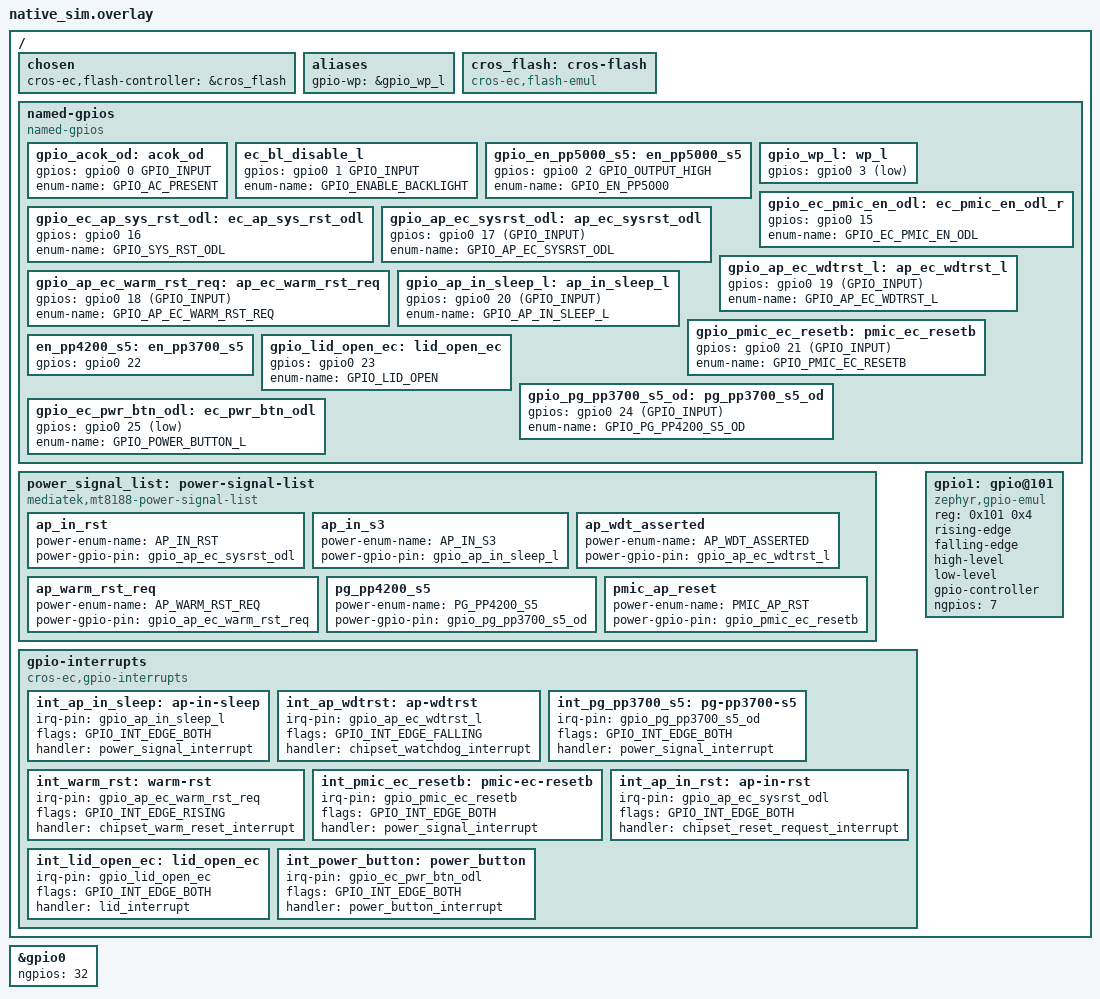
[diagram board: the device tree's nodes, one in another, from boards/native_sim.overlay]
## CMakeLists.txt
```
# Copyright 2025 The ChromiumOS Authors
# Use of this source code is governed by a BSD-style license that can be
# found in the LICENSE file.

cmake_minimum_required(VERSION 3.13.1)
find_package(Zephyr REQUIRED HINTS "${ZEPHYR_BASE}")
project(mtk_power)

# Include the local test directory for shimmed_test_tasks.h
zephyr_include_directories("${CMAKE_CURRENT_SOURCE_DIR}")

FILE(GLOB_RECURSE test_sources src/*.c)
target_sources(app PRIVATE ${test_sources})
```

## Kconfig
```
# Copyright 2025 The ChromiumOS Authors
# Use of this source code is governed by a BSD-style license that can be
# found in the LICENSE file.

source "Kconfig.zephyr"
```

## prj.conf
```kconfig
# Copyright 2025 The ChromiumOS Authors
# Use of this source code is governed by a BSD-style license that can be
# found in the LICENSE file.

CONFIG_ASSERT=y
CONFIG_TEST=y
CONFIG_ZTEST=y
CONFIG_ZTEST_ASSERT_VERBOSE=1
CONFIG_ZTEST_MOCKING=y

CONFIG_INPUT=y

# Print logs from Zephyr LOG_MODULE to stdout
CONFIG_UART_NATIVE_PTY_0_ON_STDINOUT=y

CONFIG_CROS_EC=y
CONFIG_EMUL=y
CONFIG_FLASH=y
CONFIG_GPIO=y
CONFIG_GPIO_GET_CONFIG=y
CONFIG_PLATFORM_EC=y
CONFIG_RING_BUFFER=y
CONFIG_SERIAL=y
CONFIG_SHELL_BACKEND_DUMMY=y
CONFIG_SHELL_BACKEND_DUMMY_BUF_SIZE=2000
CONFIG_SHELL_BACKEND_SERIAL=n
CONFIG_SHIMMED_TASKS=y

# MTK power sequencing
CONFIG_AP_ARM_MTK_MT8196=y
CONFIG_PLATFORM_EC_CHIPSET_RESUME_INIT_HOOK=y
CONFIG_PLATFORM_EC_EXTPOWER=y
CONFIG_PLATFORM_EC_EXTPOWER_GPIO=y
CONFIG_PLATFORM_EC_HOSTCMD=y
CONFIG_PLATFORM_EC_LID_SWITCH=y
CONFIG_PLATFORM_EC_POWERSEQ=y
CONFIG_PLATFORM_EC_POWERSEQ_HOST_SLEEP=y
CONFIG_PLATFORM_EC_POWERSEQ_MT8196=y
CONFIG_PLATFORM_EC_POWER_BUTTON=y
CONFIG_PLATFORM_EC_POWER_SLEEP_FAILURE_DETECTION=y
```

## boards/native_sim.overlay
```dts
/* Copyright 2025 The ChromiumOS Authors
 * Use of this source code is governed by a BSD-style license that can be
 * found in the LICENSE file.
 */

#include <board-overlays/native_sim.dts>
#include <dt-bindings/gpio_defines.h>
#include <cros/binman.dtsi>

/ {
	chosen {
		cros-ec,flash-controller = &cros_flash;
	};
	aliases {
		gpio-wp = &gpio_wp_l;
	};
	cros_flash: cros-flash {
		compatible = "cros-ec,flash-emul";
	};

	/*
	 * Keep these GPIOs in pin order.
	 * If you need to add one, make sure you increase
	 * ngpios in the gpio0 node further down.
	 */
	named-gpios {
		compatible = "named-gpios";

		gpio_acok_od: acok_od {
			gpios = <&gpio0 0 GPIO_INPUT>;
			enum-name = "GPIO_AC_PRESENT";
		};
		ec_bl_disable_l {
			gpios = <&gpio0 1 GPIO_INPUT>;
			enum-name = "GPIO_ENABLE_BACKLIGHT";
		};
		gpio_en_pp5000_s5: en_pp5000_s5 {
			gpios = <&gpio0 2 GPIO_OUTPUT_HIGH>;
			enum-name = "GPIO_EN_PP5000";
		};
		gpio_wp_l: wp_l {
			gpios = <&gpio0 3 (GPIO_INPUT | GPIO_ACTIVE_LOW)>;
		};
		gpio_ec_pmic_en_odl: ec_pmic_en_odl_r {
			gpios = <&gpio0 15 (GPIO_OUTPUT | GPIO_ACTIVE_HIGH | GPIO_OUTPUT_INIT_HIGH)>;
			enum-name = "GPIO_EC_PMIC_EN_ODL";
		};
		gpio_ec_ap_sys_rst_odl: ec_ap_sys_rst_odl {
			gpios = <&gpio0 16 (GPIO_OUTPUT | GPIO_ACTIVE_HIGH | GPIO_OUTPUT_INIT_HIGH)>;
			enum-name = "GPIO_SYS_RST_ODL";
		};
		gpio_ap_ec_sysrst_odl: ap_ec_sysrst_odl {
			gpios = <&gpio0 17 (GPIO_INPUT)>;
			enum-name = "GPIO_AP_EC_SYSRST_ODL";
		};
		gpio_ap_ec_warm_rst_req: ap_ec_warm_rst_req {
			gpios = <&gpio0 18 (GPIO_INPUT)>;
			enum-name = "GPIO_AP_EC_WARM_RST_REQ";
		};
		gpio_ap_ec_wdtrst_l: ap_ec_wdtrst_l {
			gpios = <&gpio0 19 (GPIO_INPUT)>;
			enum-name = "GPIO_AP_EC_WDTRST_L";
		};
		gpio_ap_in_sleep_l: ap_in_sleep_l {
			gpios = <&gpio0 20 (GPIO_INPUT)>;
			enum-name = "GPIO_AP_IN_SLEEP_L";
		};
		gpio_pmic_ec_resetb: pmic_ec_resetb {
			gpios = <&gpio0 21 (GPIO_INPUT)>;
			enum-name = "GPIO_PMIC_EC_RESETB";
		};
		/* a label to prevent build break in power sequencing */
		en_pp4200_s5: en_pp3700_s5 {
			gpios = <&gpio0 22 (GPIO_OUTPUT | GPIO_ACTIVE_HIGH | GPIO_OUTPUT_INIT_LOW)>;
		};
		gpio_lid_open_ec: lid_open_ec {
			/* GPIO_PULL_UP will cause this start asserted. */
			gpios = <&gpio0 23 (GPIO_INPUT | GPIO_PULL_UP)>;
			enum-name = "GPIO_LID_OPEN";
		};
		gpio_pg_pp3700_s5_od: pg_pp3700_s5_od {
			gpios = <&gpio0 24 (GPIO_INPUT)>;
			enum-name = "GPIO_PG_PP4200_S5_OD";
		};
		gpio_ec_pwr_btn_odl: ec_pwr_btn_odl {
			/* GPIO_PULL_UP will cause this start asserted,
			 * i.e. not pressed.
			 */
			gpios = <&gpio0 25 (GPIO_INPUT | GPIO_ACTIVE_LOW | GPIO_PULL_UP)>;
			enum-name = "GPIO_POWER_BUTTON_L";
		};
	};

	power_signal_list: power-signal-list {
		compatible = "mediatek,mt8188-power-signal-list";

		ap_in_rst {
			power-enum-name = "AP_IN_RST";
			power-gpio-pin = <&gpio_ap_ec_sysrst_odl>;
		};
		ap_in_s3 {
			power-enum-name = "AP_IN_S3";
			power-gpio-pin = <&gpio_ap_in_sleep_l>;
		};
		ap_wdt_asserted {
			power-enum-name = "AP_WDT_ASSERTED";
			power-gpio-pin = <&gpio_ap_ec_wdtrst_l>;
		};
		ap_warm_rst_req {
			power-enum-name = "AP_WARM_RST_REQ";
			power-gpio-pin = <&gpio_ap_ec_warm_rst_req>;
		};
		pg_pp4200_s5 {
			/*
			 * It's actually PP3700, but we don't change it and
			 * follow the legacy naming.
			 */
			power-enum-name = "PG_PP4200_S5";
			power-gpio-pin = <&gpio_pg_pp3700_s5_od>;
		};
		pmic_ap_reset {
			power-enum-name = "PMIC_AP_RST";
			power-gpio-pin = <&gpio_pmic_ec_resetb>;
		};
	};

	gpio-interrupts {
		compatible = "cros-ec,gpio-interrupts";

		int_ap_in_sleep: ap-in-sleep {
			irq-pin = <&gpio_ap_in_sleep_l>;
			flags = <GPIO_INT_EDGE_BOTH>;
			handler = "power_signal_interrupt";
		};
		int_ap_wdtrst: ap-wdtrst {
			irq-pin = <&gpio_ap_ec_wdtrst_l>;
			flags = <GPIO_INT_EDGE_FALLING>;
			handler = "chipset_watchdog_interrupt";
		};
		int_pg_pp3700_s5: pg-pp3700-s5 {
			irq-pin = <&gpio_pg_pp3700_s5_od>;
			flags = <GPIO_INT_EDGE_BOTH>;
			handler = "power_signal_interrupt";
		};
		int_warm_rst: warm-rst {
			irq-pin = <&gpio_ap_ec_warm_rst_req>;
			flags = <GPIO_INT_EDGE_RISING>;
			handler = "chipset_warm_reset_interrupt";
		};
		int_pmic_ec_resetb: pmic-ec-resetb {
			irq-pin = <&gpio_pmic_ec_resetb>;
			flags = <GPIO_INT_EDGE_BOTH>;
			handler = "power_signal_interrupt";
		};
		int_ap_in_rst: ap-in-rst {
			irq-pin = <&gpio_ap_ec_sysrst_odl>;
			flags = <GPIO_INT_EDGE_BOTH>;
			handler = "chipset_reset_request_interrupt";
		};
		int_lid_open_ec: lid_open_ec {
			irq-pin = <&gpio_lid_open_ec>;
			flags = <GPIO_INT_EDGE_BOTH>;
			handler = "lid_interrupt";
		};
		int_power_button: power_button {
			irq-pin = <&gpio_ec_pwr_btn_odl>;
			flags = <GPIO_INT_EDGE_BOTH>;
			handler = "power_button_interrupt";
		};
	};

	gpio1: gpio@101 {
		status = "okay";
		compatible = "zephyr,gpio-emul";
		reg = <0x101 0x4>;
		rising-edge;
		falling-edge;
		high-level;
		low-level;
		gpio-controller;
		#gpio-cells = <2>;
		ngpios = <7>;
	};
};

&gpio0 {
	ngpios = <32>;
};
```

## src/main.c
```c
/* Copyright 2025 The ChromiumOS Authors
 * Use of this source code is governed by a BSD-style license that can be
 * found in the LICENSE file.
 */

#include "console.h"
#include "ec_app_main.h"
#include "gpio.h"
#include "gpio_signal.h"
#include "hooks.h"
#include "host_command.h"
#include "include/power_button.h"
#include "lid_switch.h"
#include "power.h"
#include "power/mt8186.h"
#include "task.h"

#include <setjmp.h>

#include <zephyr/device.h>
#include <zephyr/devicetree.h>
#include <zephyr/drivers/gpio.h>
#include <zephyr/drivers/gpio/gpio_emul.h>
#include <zephyr/fff.h>
#include <zephyr/input/input.h>
#include <zephyr/kernel.h>
#include <zephyr/logging/log.h>
#include <zephyr/shell/shell_dummy.h>
#include <zephyr/ztest.h>

#include <dt-bindings/buttons.h>

LOG_MODULE_REGISTER(mtk_power, LOG_LEVEL_INF);

/* For simplicity, enforce that all the gpios are on the same controller. */
#define GPIO_DEVICE    \
	DEVICE_DT_GET( \
		DT_GPIO_CTLR(NAMED_GPIOS_GPIO_NODE(ap_ec_sysrst_odl), gpios))
#define ASSERT_SAME_CONTROLLER(x)                                           \
	BUILD_ASSERT(                                                       \
		DT_DEP_ORD(DT_GPIO_CTLR(                                    \
			NAMED_GPIOS_GPIO_NODE(ap_ec_sysrst_odl), gpios)) == \
		DT_DEP_ORD(DT_GPIO_CTLR(NAMED_GPIOS_GPIO_NODE(x), gpios)))

#define AP_IN_RST DT_GPIO_PIN(NAMED_GPIOS_GPIO_NODE(ap_ec_sysrst_odl), gpios)
ASSERT_SAME_CONTROLLER(ap_ec_sysrst_odl);
#define EC_AP_RST_L DT_GPIO_PIN(NAMED_GPIOS_GPIO_NODE(ec_ap_sys_rst_odl), gpios)
ASSERT_SAME_CONTROLLER(ec_ap_sys_rst_odl);
#define AP_IN_SLEEP DT_GPIO_PIN(NAMED_GPIOS_GPIO_NODE(ap_in_sleep_l), gpios)
ASSERT_SAME_CONTROLLER(ap_in_sleep_l);
#define AP_WARM_RST_REQ \
	DT_GPIO_PIN(NAMED_GPIOS_GPIO_NODE(ap_ec_warm_rst_req), gpios)
ASSERT_SAME_CONTROLLER(ap_ec_warm_rst_req);
#define AP_WDGT_RST_REQ \
	DT_GPIO_PIN(NAMED_GPIOS_GPIO_NODE(ap_ec_wdtrst_l), gpios)
ASSERT_SAME_CONTROLLER(ap_ec_wdtrst_l);
#define PG_PP3700_S5 DT_GPIO_PIN(NAMED_GPIOS_GPIO_NODE(pg_pp3700_s5_od), gpios)
ASSERT_SAME_CONTROLLER(pg_pp3700_s5_od);
#define LID_OPEN_EC_PIN DT_GPIO_PIN(NAMED_GPIOS_GPIO_NODE(lid_open_ec), gpios)
ASSERT_SAME_CONTROLLER(lid_open_ec);
#define PMIC_EC_RESETB DT_GPIO_PIN(NAMED_GPIOS_GPIO_NODE(pmic_ec_resetb), gpios)
ASSERT_SAME_CONTROLLER(pmic_ec_resetb);

DEFINE_FFF_GLOBALS;

FAKE_VALUE_FUNC(int, system_can_boot_ap);
FAKE_VALUE_FUNC(int, battery_wait_for_stable);

extern bool is_held;

static struct gpio_callback gpio_callback;

int battery_is_present(void)
{
	return 1;
}

void mtk_set_power_state(enum power_state target)
{
	static const struct device *gpio_dev = GPIO_DEVICE;

	if (target == POWER_S0) {
		power_signal_enable_interrupt(GPIO_AP_EC_SYSRST_ODL);
		power_signal_enable_interrupt(GPIO_AP_IN_SLEEP_L);
		zassert_ok(gpio_emul_input_set(gpio_dev, AP_IN_RST, 0));
		zassert_ok(gpio_emul_input_set(gpio_dev, AP_IN_SLEEP, 0));
		zassert_ok(gpio_emul_input_set(gpio_dev, PG_PP3700_S5, 1));
		zassert_ok(gpio_pin_set(gpio_dev, EC_AP_RST_L, 1));
		zassert_ok(gpio_emul_input_set(gpio_dev, LID_OPEN_EC_PIN, 1));
		zassert_ok(gpio_emul_input_set(gpio_dev, PMIC_EC_RESETB, 0));
		power_signal_interrupt(GPIO_AP_IN_SLEEP_L);

		task_wake(TASK_ID_CHIPSET);
		/* Wait for power state transition. */
		k_sleep(K_MSEC(500));
		is_held = false;
	} else if (target == POWER_S3) {
		/* preconditions */
		power_signal_enable_interrupt(GPIO_AP_IN_SLEEP_L);
		zassert_ok(gpio_emul_input_set(gpio_dev, AP_IN_SLEEP, 1));
		task_wake(TASK_ID_CHIPSET);
		/* wait for S3 processing */
		k_sleep(K_MSEC(10));
	} else if (target == POWER_G3) {
		zassert_ok(gpio_emul_input_set(gpio_dev, AP_WDGT_RST_REQ, 1));
		k_sleep(K_MSEC(1));
		zassert_ok(gpio_emul_input_set(gpio_dev, AP_WDGT_RST_REQ, 0));
		zassert_ok(gpio_emul_input_set(gpio_dev, AP_IN_RST, 1));
		zassert_ok(gpio_emul_input_set(gpio_dev, AP_IN_SLEEP, 1));
		zassert_ok(gpio_emul_input_set(gpio_dev, PMIC_EC_RESETB, 1));
		zassert_ok(gpio_emul_input_set(gpio_dev, PG_PP3700_S5, 0));
		/* simulate watchdog signal toggle during shutdown */
		task_wake(TASK_ID_CHIPSET);
		/* Wait for power state transition. */
		k_sleep(K_SECONDS(11));
	} else {
		/* unsupported power state */
		zassert_ok(false);
		return;
	}
	zassert_equal(power_get_state(), target);
}

ZTEST(mtk_power, test_watchdog_reset_in_s3)
{
	static const struct device *gpio_dev = GPIO_DEVICE;
	int reset_count = test_chipset_get_ap_resets_since_ec_boot();

	mtk_set_power_state(POWER_S3);

	if (IS_ENABLED(CONFIG_PLATFORM_EC_POWERSEQ_MTK_DOUBLE_WDT)) {
		/*
		 * CONFIG_PLATFORM_EC_POWERSEQ_MTK_DOUBLE_WDT=y
		 * Verify that first WDT doesn't trigger reset
		 */

		zassert_ok(gpio_emul_input_set(gpio_dev, AP_WDGT_RST_REQ, 1));
		k_sleep(K_MSEC(1));
		zassert_ok(gpio_emul_input_set(gpio_dev, AP_WDGT_RST_REQ, 0));
		k_sleep(K_MSEC(160));

		zassert_equal(test_chipset_get_ap_resets_since_ec_boot(),
			      reset_count);
	}

	/* Trigger AP watchdog. */
	zassert_ok(gpio_emul_input_set(gpio_dev, AP_WDGT_RST_REQ, 1));
	k_sleep(K_MSEC(1));
	zassert_ok(gpio_emul_input_set(gpio_dev, AP_WDGT_RST_REQ, 0));

	/* Wait 150+ms for debouncing fake AP watchdog interrupt */
	k_sleep(K_MSEC(160));
	zassert_equal(test_chipset_get_ap_resets_since_ec_boot(),
		      reset_count + 1);
	zassert_equal(chipset_get_shutdown_reason(), CHIPSET_RESET_AP_WATCHDOG);
}

ZTEST(mtk_power, test_double_wdt_timeout)
{
	Z_TEST_SKIP_IFNDEF(CONFIG_PLATFORM_EC_POWERSEQ_MTK_DOUBLE_WDT);

	static const struct device *gpio_dev = GPIO_DEVICE;
	int reset_count = test_chipset_get_ap_resets_since_ec_boot();

	/* Trigger AP watchdog. */
	zassert_ok(gpio_emul_input_set(gpio_dev, AP_WDGT_RST_REQ, 1));
	k_sleep(K_MSEC(1));
	zassert_ok(gpio_emul_input_set(gpio_dev, AP_WDGT_RST_REQ, 0));

	/* Wait 150+ms for debouncing fake AP watchdog interrupt */
	k_sleep(K_MSEC(160));
	zassert_equal(test_chipset_get_ap_resets_since_ec_boot(), reset_count);

	k_sleep(K_SECONDS(20));
	zassert_equal(test_chipset_get_ap_resets_since_ec_boot(),
		      reset_count + 1);
	zassert_equal(chipset_get_shutdown_reason(), CHIPSET_RESET_AP_WATCHDOG);
}

/* watchdog should be ignored during shutdown */
ZTEST(mtk_power, test_shutdown)
{
	int reset_count = test_chipset_get_ap_resets_since_ec_boot();

	mtk_set_power_state(POWER_G3);
	mtk_set_power_state(POWER_S0);
	k_sleep(K_SECONDS(20));

	zassert_equal(test_chipset_get_ap_resets_since_ec_boot(), reset_count);
}

void start_in_s0(void *fixture)
{
	RESET_FAKE(system_can_boot_ap);
	system_can_boot_ap_fake.return_val = 1;

	mtk_set_power_state(POWER_S0);
	zassert_equal(power_has_signals(POWER_SIGNAL_MASK(0)), 0);
}

void mtk_cleanup(void *fixture)
{
	if (gpio_callback.handler != NULL) {
		static const struct device *gpio_dev = GPIO_DEVICE;

		gpio_remove_callback(gpio_dev, &gpio_callback);
		gpio_callback.handler = NULL;
	}
	host_clear_events(EC_HOST_EVENT_MASK(EC_HOST_EVENT_HANG_DETECT));
	system_clear_reset_flags(EC_RESET_FLAG_SYSJUMP | EC_RESET_FLAG_AP_OFF);
}

ZTEST_SUITE(mtk_power, NULL, NULL, start_in_s0, mtk_cleanup, NULL);

void test_main(void)
{
	ec_app_main();
	/* Fake sleep long enough to go to S5 and back to G3 again. */
	k_sleep(K_SECONDS(11));

	ztest_run_test_suites(NULL, false, 1, 1);

	ztest_verify_all_test_suites_ran();
}
```
